VERSION ""

NS_ :

BS_:

BU_: ads_s2

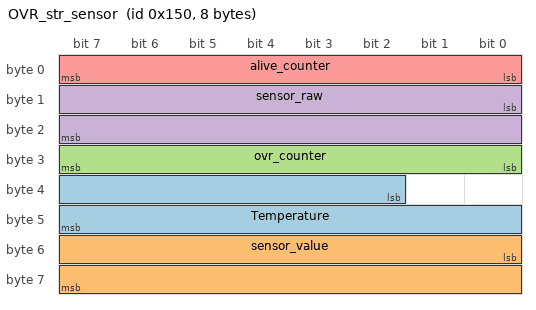
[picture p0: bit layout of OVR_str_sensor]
BO_ 336 OVR_str_sensor: 8 ads_s2
 SG_ Temperature : 34|14@1+ (0.01,-40) [-40|123.83] "degC" Vector__XXX
 SG_ sensor_value : 48|16@1- (0.001,0) [-32.768|32.767] "" Vector__XXX
 SG_ ovr_counter : 24|8@1+ (1,0) [0|255] "" Vector__XXX
 SG_ sensor_raw : 8|16@1- (0.001,0) [-32.768|32.767] "" Vector__XXX
 SG_ alive_counter : 0|8@1+ (1,0) [0|255] "" Vector__XXX

BA_DEF_  "BusType" STRING ;
BA_DEF_DEF_  "BusType" "CAN";
